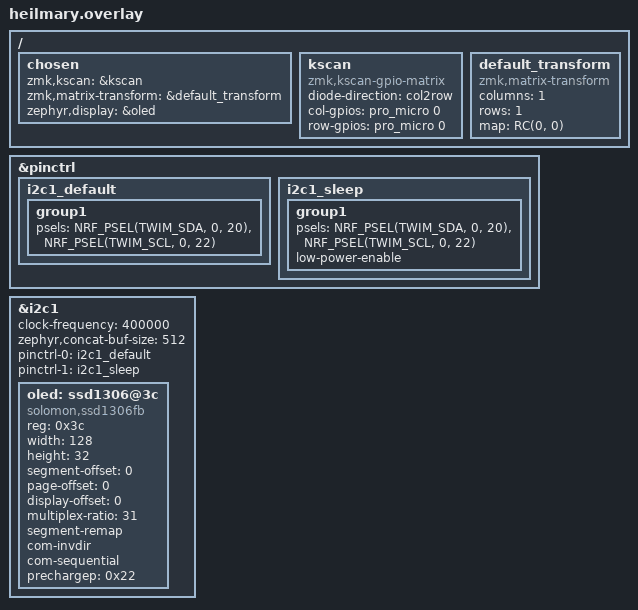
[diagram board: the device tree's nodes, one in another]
#include <dt-bindings/zmk/matrix_transform.h>
#include <dt-bindings/pinctrl/nrf-pinctrl.h>

&pinctrl {
    i2c1_default: i2c1_default {
        group1 {
            psels = <NRF_PSEL(TWIM_SDA, 0, 20)>,
                <NRF_PSEL(TWIM_SCL, 0, 22)>;
        };
    };
    i2c1_sleep: i2c1_sleep {
        group1 {
            psels = <NRF_PSEL(TWIM_SDA, 0, 20)>,
                <NRF_PSEL(TWIM_SCL, 0, 22)>;
            low-power-enable;
        };
    };
};

/ {
    chosen {
        zmk,kscan = &kscan;
        zmk,matrix-transform = &default_transform;
        zephyr,display = &oled;
    };

    kscan: kscan {
        compatible = "zmk,kscan-gpio-matrix";
        diode-direction = "col2row";
        col-gpios = <&pro_micro 0 GPIO_ACTIVE_HIGH>;
        row-gpios = <&pro_micro 0 (GPIO_ACTIVE_HIGH | GPIO_PULL_DOWN)>;
    };

    default_transform: default_transform {
        compatible = "zmk,matrix-transform";
        columns = <1>;
        rows = <1>;
        map = <RC(0, 0)>;
    };
};

&i2c1 {
    status = "okay";
    clock-frequency = <400000>;
    zephyr,concat-buf-size = <512>;
    pinctrl-0 = <&i2c1_default>;
    pinctrl-1 = <&i2c1_sleep>;
    pinctrl-names = "default", "sleep";

    oled: ssd1306@3c {
        compatible = "solomon,ssd1306fb";
        reg = <0x3c>;
        width = <128>;
        height = <32>;
        segment-offset = <0>;
        page-offset = <0>;
        display-offset = <0>;
        multiplex-ratio = <31>;
        segment-remap;
        com-invdir;
        com-sequential;
        prechargep = <0x22>;
    };
};
